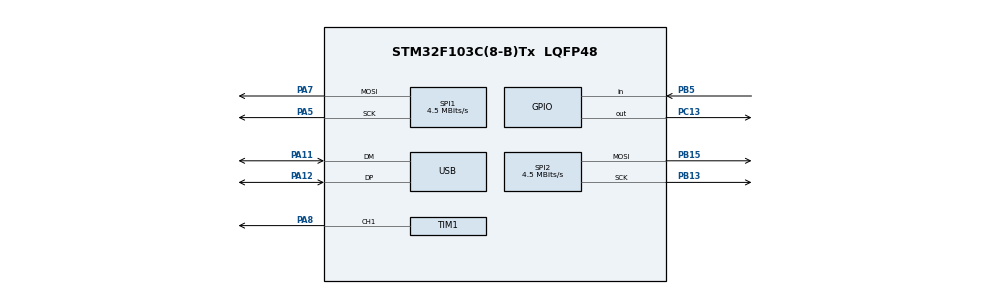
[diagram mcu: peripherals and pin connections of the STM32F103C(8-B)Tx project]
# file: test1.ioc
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Mcu.Family=STM32F1
Dma.SPI2_TX.1.MemInc=DMA_MINC_ENABLE
Dma.SPI1_TX.0.MemInc=DMA_MINC_ENABLE
USB_DEVICE.CLASS_NAME_FS=CDC
Dma.SPI1_TX.0.PeriphInc=DMA_PINC_DISABLE
PA7.Mode=TX_Only_Simplex_Unidirect_Master
NVIC.DMA1_Channel5_IRQn=true\:0\:0\:false\:false\:true\:false\:true
PD1-OSC_OUT.Mode=HSE-External-Oscillator
SPI1.VirtualType=VM_MASTER
SPI2.VirtualType=VM_MASTER
USB_DEVICE.VirtualModeFS=Cdc_FS
TIM1.Channel-Output\ Compare2\ No\ Output=TIM_CHANNEL_2
Dma.SPI2_TX.1.PeriphInc=DMA_PINC_DISABLE
PC13-TAMPER-RTC.Signal=GPIO_Output
RCC.USBPrescaler=RCC_USBCLKSOURCE_PLL_DIV1_5
TIM1.OC2Preload=ENABLE
PA11.Mode=Device
SPI1.CLKPhase=SPI_PHASE_2EDGE
PD0-OSC_IN.Signal=RCC_OSC_IN
TIM1.Pulse-PWM\ Generation1\ CH1=400
RCC.APB1CLKDivider=RCC_HCLK_DIV2
PB13.Signal=SPI2_SCK
PB15.Signal=SPI2_MOSI
RCC.SYSCLKSource=RCC_SYSCLKSOURCE_PLLCLK
ProjectManager.StackSize=0x400
PD1-OSC_OUT.Signal=RCC_OSC_OUT
NVIC.DMA1_Channel3_IRQn=true\:0\:0\:false\:false\:true\:false\:true
PA13.Signal=SYS_JTMS-SWDIO
PA12.Signal=USB_DP
SH.S_TIM1_CH1.0=TIM1_CH1,PWM Generation1 CH1
SPI1.CLKPolarity=SPI_POLARITY_HIGH
SPI2.CLKPolarity=SPI_POLARITY_HIGH
ProjectManager.TargetToolchain=STM32CubeIDE
SPI1.Direction=SPI_DIRECTION_2LINES
Dma.SPI1_TX.0.PeriphDataAlignment=DMA_PDATAALIGN_HALFWORD
RCC.HCLKFreq_Value=72000000
Dma.SPI1_TX.0.Direction=DMA_MEMORY_TO_PERIPH
VP_USB_DEVICE_VS_USB_DEVICE_CDC_FS.Mode=CDC_FS
RCC.APB2TimFreq_Value=72000000
TIM1.Pulse-Output\ Compare2\ No\ Output=50
SPI1.CalculateBaudRate=4.5 MBits/s
RCC.USBFreq_Value=48000000
RCC.AHBFreq_Value=72000000
SPI2.BaudRatePrescaler=SPI_BAUDRATEPRESCALER_8
PD0-OSC_IN.Mode=HSE-External-Oscillator
PA5.Signal=SPI1_SCK
board=custom
Dma.SPI2_TX.1.Direction=DMA_MEMORY_TO_PERIPH
RCC.PLLMUL=RCC_PLL_MUL9
PB15.Mode=TX_Only_Simplex_Unidirect_Master
RCC.APB2Freq_Value=72000000
Dma.SPI2_TX.1.PeriphDataAlignment=DMA_PDATAALIGN_HALFWORD
TIM1.Channel-PWM\ Generation1\ CH1=TIM_CHANNEL_1
SPI1.Mode=SPI_MODE_MASTER
PA14.Mode=Serial_Wire
Dma.SPI2_TX.1.Priority=DMA_PRIORITY_HIGH
NVIC.USB_LP_CAN1_RX0_IRQn=true\:1\:0\:true\:false\:true\:false\:true
SPI1.DataSize=SPI_DATASIZE_16BIT
SPI2.CalculateBaudRate=4.5 MBits/s
Dma.SPI1_TX.0.Instance=DMA1_Channel3
PA8.Signal=S_TIM1_CH1
VP_TIM1_VS_no_output2.Mode=Output Compare2 No Output
PA13.Mode=Serial_Wire
Mcu.Name=STM32F103C(8-B)Tx
VP_TIM1_VS_ClockSourceINT.Mode=Internal
NVIC.TIM1_CC_IRQn=true\:0\:0\:false\:false\:true\:true\:true
Dma.SPI1_TX.0.Mode=DMA_NORMAL
RCC.SYSCLKFreq_VALUE=72000000
Mcu.Package=LQFP48
PB5.Signal=GPIO_Input
Dma.SPI2_TX.1.Mode=DMA_NORMAL
SPI2.Mode=SPI_MODE_MASTER
PA12.Mode=Device
PA11.Signal=USB_DM
PA14.Signal=SYS_JTCK-SWCLK
ProjectManager.HeapSize=0x200
Dma.SPI1_TX.0.Priority=DMA_PRIORITY_HIGH
Dma.SPI1_TX.0.MemDataAlignment=DMA_MDATAALIGN_HALFWORD
Dma.SPI2_TX.1.Instance=DMA1_Channel5
SPI2.CLKPhase=SPI_PHASE_2EDGE
NVIC.PriorityGroup=NVIC_PRIORITYGROUP_4
Dma.Request1=SPI2_TX
RCC.APB1TimFreq_Value=72000000
SPI2.DataSize=SPI_DATASIZE_16BIT
SPI2.Direction=SPI_DIRECTION_2LINES
TIM1.Period=13636
PB13.Mode=TX_Only_Simplex_Unidirect_Master
Dma.Request0=SPI1_TX
RCC.APB1Freq_Value=36000000
SPI1.BaudRatePrescaler=SPI_BAUDRATEPRESCALER_16
USB_DEVICE.VirtualMode=Cdc
Dma.SPI2_TX.1.MemDataAlignment=DMA_MDATAALIGN_HALFWORD
PA5.Mode=TX_Only_Simplex_Unidirect_Master
PA7.Signal=SPI1_MOSI

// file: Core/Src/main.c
/* USER CODE BEGIN Header */
/**
  ******************************************************************************
  * @file           : main.c
  * @brief          : Main program body
  ******************************************************************************
  * @attention
  *
  * <h2><center>&copy; Copyright (c) 2021 STMicroelectronics.
  * All rights reserved.</center></h2>
  *
  * This software component is licensed by ST under BSD 3-Clause license,
  * the "License"; You may not use this file except in compliance with the
  * License. You may obtain a copy of the License at:
  *                        opensource.org/licenses/BSD-3-Clause
  *
  ******************************************************************************
  */
/* USER CODE END Header */
#include "main.h"
#include "usb_device.h"

/* USER CODE BEGIN Includes */
#include "user.h"
/* USER CODE END Includes */

SPI_HandleTypeDef hspi1;
SPI_HandleTypeDef hspi2;
DMA_HandleTypeDef hdma_spi1_tx;
DMA_HandleTypeDef hdma_spi2_tx;

void SystemClock_Config(void);
static void MX_GPIO_Init(void);
static void MX_DMA_Init(void);
static void MX_SPI1_Init(void);
static void MX_SPI2_Init(void);
static void MX_TIM1_Init(void);

int main(void)
{

  /* MCU Configuration--------------------------------------------------------*/

  /* Reset of all peripherals, Initializes the Flash interface and the Systick. */
  HAL_Init();

  /* Configure the system clock */
  SystemClock_Config();

  /* Initialize all configured peripherals */
  MX_GPIO_Init();
  MX_DMA_Init();
  MX_SPI1_Init();
  MX_SPI2_Init();
  MX_USB_DEVICE_Init();
  MX_TIM1_Init();
  /* USER CODE BEGIN 2 */
  init();
  /* USER CODE END 2 */

  /* Infinite loop */
  while (1)
  {

  }
}

void SystemClock_Config(void)
{
  LL_FLASH_SetLatency(LL_FLASH_LATENCY_2);
  while(LL_FLASH_GetLatency()!= LL_FLASH_LATENCY_2)
  {
  }
  LL_RCC_HSE_Enable();

   /* Wait till HSE is ready */
  while(LL_RCC_HSE_IsReady() != 1)
  {

  }
  LL_RCC_PLL_ConfigDomain_SYS(LL_RCC_PLLSOURCE_HSE_DIV_1, LL_RCC_PLL_MUL_9);
  LL_RCC_PLL_Enable();

   /* Wait till PLL is ready */
  while(LL_RCC_PLL_IsReady() != 1)
  {

  }
  LL_RCC_SetAHBPrescaler(LL_RCC_SYSCLK_DIV_1);
  LL_RCC_SetAPB1Prescaler(LL_RCC_APB1_DIV_2);
  LL_RCC_SetAPB2Prescaler(LL_RCC_APB2_DIV_1);
  LL_RCC_SetSysClkSource(LL_RCC_SYS_CLKSOURCE_PLL);

   /* Wait till System clock is ready */
  while(LL_RCC_GetSysClkSource() != LL_RCC_SYS_CLKSOURCE_STATUS_PLL)
  {

  }
  LL_SetSystemCoreClock(72000000);

   /* Update the time base */
  if (HAL_InitTick (TICK_INT_PRIORITY) != HAL_OK)
  {
    Error_Handler();
  }
  LL_RCC_SetUSBClockSource(LL_RCC_USB_CLKSOURCE_PLL_DIV_1_5);
}

static void MX_SPI1_Init(void)
{

  /* SPI1 parameter configuration*/
  hspi1.Instance = SPI1;
  hspi1.Init.Mode = SPI_MODE_MASTER;
  hspi1.Init.Direction = SPI_DIRECTION_2LINES;
  hspi1.Init.DataSize = SPI_DATASIZE_16BIT;
  hspi1.Init.CLKPolarity = SPI_POLARITY_HIGH;
  hspi1.Init.CLKPhase = SPI_PHASE_2EDGE;
  hspi1.Init.NSS = SPI_NSS_SOFT;
  hspi1.Init.BaudRatePrescaler = SPI_BAUDRATEPRESCALER_16;
  hspi1.Init.FirstBit = SPI_FIRSTBIT_MSB;
  hspi1.Init.TIMode = SPI_TIMODE_DISABLE;
  hspi1.Init.CRCCalculation = SPI_CRCCALCULATION_DISABLE;
  hspi1.Init.CRCPolynomial = 10;
  if (HAL_SPI_Init(&hspi1) != HAL_OK)
  {
    Error_Handler();
  }

}

static void MX_SPI2_Init(void)
{

  /* SPI2 parameter configuration*/
  hspi2.Instance = SPI2;
  hspi2.Init.Mode = SPI_MODE_MASTER;
  hspi2.Init.Direction = SPI_DIRECTION_2LINES;
  hspi2.Init.DataSize = SPI_DATASIZE_16BIT;
  hspi2.Init.CLKPolarity = SPI_POLARITY_HIGH;
  hspi2.Init.CLKPhase = SPI_PHASE_2EDGE;
  hspi2.Init.NSS = SPI_NSS_SOFT;
  hspi2.Init.BaudRatePrescaler = SPI_BAUDRATEPRESCALER_8;
  hspi2.Init.FirstBit = SPI_FIRSTBIT_MSB;
  hspi2.Init.TIMode = SPI_TIMODE_DISABLE;
  hspi2.Init.CRCCalculation = SPI_CRCCALCULATION_DISABLE;
  hspi2.Init.CRCPolynomial = 10;
  if (HAL_SPI_Init(&hspi2) != HAL_OK)
  {
    Error_Handler();
  }

}

static void MX_TIM1_Init(void)
{

  LL_TIM_InitTypeDef TIM_InitStruct = {0};
  LL_TIM_OC_InitTypeDef TIM_OC_InitStruct = {0};
  LL_TIM_BDTR_InitTypeDef TIM_BDTRInitStruct = {0};

  LL_GPIO_InitTypeDef GPIO_InitStruct = {0};

  /* Peripheral clock enable */
  LL_APB2_GRP1_EnableClock(LL_APB2_GRP1_PERIPH_TIM1);

  /* TIM1 interrupt Init */
  NVIC_SetPriority(TIM1_CC_IRQn, NVIC_EncodePriority(NVIC_GetPriorityGrouping(),0, 0));
  NVIC_EnableIRQ(TIM1_CC_IRQn);

  TIM_InitStruct.Prescaler = 0;
  TIM_InitStruct.CounterMode = LL_TIM_COUNTERMODE_UP;
  TIM_InitStruct.Autoreload = 13636;
  TIM_InitStruct.ClockDivision = LL_TIM_CLOCKDIVISION_DIV1;
  TIM_InitStruct.RepetitionCounter = 0;
  LL_TIM_Init(TIM1, &TIM_InitStruct);
  LL_TIM_DisableARRPreload(TIM1);
  LL_TIM_SetClockSource(TIM1, LL_TIM_CLOCKSOURCE_INTERNAL);
  LL_TIM_OC_EnablePreload(TIM1, LL_TIM_CHANNEL_CH1);
  TIM_OC_InitStruct.OCMode = LL_TIM_OCMODE_PWM1;
  TIM_OC_InitStruct.OCState = LL_TIM_OCSTATE_DISABLE;
  TIM_OC_InitStruct.OCNState = LL_TIM_OCSTATE_DISABLE;
  TIM_OC_InitStruct.CompareValue = 400;
  TIM_OC_InitStruct.OCPolarity = LL_TIM_OCPOLARITY_HIGH;
  TIM_OC_InitStruct.OCNPolarity = LL_TIM_OCPOLARITY_HIGH;
  TIM_OC_InitStruct.OCIdleState = LL_TIM_OCIDLESTATE_LOW;
  TIM_OC_InitStruct.OCNIdleState = LL_TIM_OCIDLESTATE_LOW;
  LL_TIM_OC_Init(TIM1, LL_TIM_CHANNEL_CH1, &TIM_OC_InitStruct);
  LL_TIM_OC_DisableFast(TIM1, LL_TIM_CHANNEL_CH1);
  TIM_OC_InitStruct.OCMode = LL_TIM_OCMODE_FROZEN;
  TIM_OC_InitStruct.CompareValue = 50;
  LL_TIM_OC_Init(TIM1, LL_TIM_CHANNEL_CH2, &TIM_OC_InitStruct);
  LL_TIM_OC_DisableFast(TIM1, LL_TIM_CHANNEL_CH2);
  LL_TIM_SetTriggerOutput(TIM1, LL_TIM_TRGO_RESET);
  LL_TIM_DisableMasterSlaveMode(TIM1);
  LL_TIM_OC_EnablePreload(TIM1, LL_TIM_CHANNEL_CH2);
  TIM_BDTRInitStruct.OSSRState = LL_TIM_OSSR_DISABLE;
  TIM_BDTRInitStruct.OSSIState = LL_TIM_OSSI_DISABLE;
  TIM_BDTRInitStruct.LockLevel = LL_TIM_LOCKLEVEL_OFF;
  TIM_BDTRInitStruct.DeadTime = 0;
  TIM_BDTRInitStruct.BreakState = LL_TIM_BREAK_DISABLE;
  TIM_BDTRInitStruct.BreakPolarity = LL_TIM_BREAK_POLARITY_HIGH;
  TIM_BDTRInitStruct.AutomaticOutput = LL_TIM_AUTOMATICOUTPUT_DISABLE;
  LL_TIM_BDTR_Init(TIM1, &TIM_BDTRInitStruct);
  LL_APB2_GRP1_EnableClock(LL_APB2_GRP1_PERIPH_GPIOA);
  /**TIM1 GPIO Configuration
  PA8   ------> TIM1_CH1
  */
  GPIO_InitStruct.Pin = LL_GPIO_PIN_8;
  GPIO_InitStruct.Mode = LL_GPIO_MODE_ALTERNATE;
  GPIO_InitStruct.Speed = LL_GPIO_SPEED_FREQ_LOW;
  GPIO_InitStruct.OutputType = LL_GPIO_OUTPUT_PUSHPULL;
  LL_GPIO_Init(GPIOA, &GPIO_InitStruct);

}

static void MX_DMA_Init(void)
{

  /* DMA controller clock enable */
  __HAL_RCC_DMA1_CLK_ENABLE();

  /* DMA interrupt init */
  /* DMA1_Channel3_IRQn interrupt configuration */
  HAL_NVIC_SetPriority(DMA1_Channel3_IRQn, 0, 0);
  HAL_NVIC_EnableIRQ(DMA1_Channel3_IRQn);
  /* DMA1_Channel5_IRQn interrupt configuration */
  HAL_NVIC_SetPriority(DMA1_Channel5_IRQn, 0, 0);
  HAL_NVIC_EnableIRQ(DMA1_Channel5_IRQn);

}

static void MX_GPIO_Init(void)
{
  LL_GPIO_InitTypeDef GPIO_InitStruct = {0};

  /* GPIO Ports Clock Enable */
  LL_APB2_GRP1_EnableClock(LL_APB2_GRP1_PERIPH_GPIOC);
  LL_APB2_GRP1_EnableClock(LL_APB2_GRP1_PERIPH_GPIOD);
  LL_APB2_GRP1_EnableClock(LL_APB2_GRP1_PERIPH_GPIOA);
  LL_APB2_GRP1_EnableClock(LL_APB2_GRP1_PERIPH_GPIOB);

  /**/
  LL_GPIO_ResetOutputPin(GPIOC, LL_GPIO_PIN_13);

  /**/
  GPIO_InitStruct.Pin = LL_GPIO_PIN_13;
  GPIO_InitStruct.Mode = LL_GPIO_MODE_OUTPUT;
  GPIO_InitStruct.Speed = LL_GPIO_SPEED_FREQ_LOW;
  GPIO_InitStruct.OutputType = LL_GPIO_OUTPUT_PUSHPULL;
  LL_GPIO_Init(GPIOC, &GPIO_InitStruct);

  /**/
  GPIO_InitStruct.Pin = LL_GPIO_PIN_5;
  GPIO_InitStruct.Mode = LL_GPIO_MODE_FLOATING;
  LL_GPIO_Init(GPIOB, &GPIO_InitStruct);

}

void Error_Handler(void)
{
  __disable_irq();
  while (1)
  {
  }
}

/************************ (C) COPYRIGHT STMicroelectronics *****END OF FILE****/
